# G32F031 register map
File version: 1.0
CPU: CM0PLUS r0p1, little endian, no MPU, no FPU, 2 interrupt priority bits
Registers are 32-bit, read-write, reset 0x0 unless marked. A register's access mark holds for its fields unless they carry their own. Offsets are from the block's base; [hi:lo] are bit positions; {n}, {i} and the like mark numbered series; 'fields as' and 'values as' point back to an identical list.

## COMP0 — Comparator
Base 0x40005C00
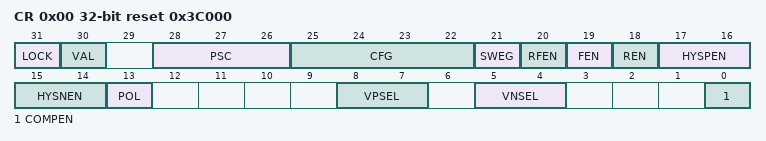
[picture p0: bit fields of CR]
0x00 CR access per field reset 0x3C000 — Control Register
  [31] LOCK rw
  [30] VAL ro — Comparator outputs the level value before polarity selector and shielding.
  [28:26] PSC rw — Digital filter fractional division configuration
  [25:22] CFG rw — Digital filter fractional clock configuration
  [21] SWEG rw — soft interrupt
  [20] RFEN rw — Comparator interrupt rising and falling edge enable
  [19] FEN rw — Comparator interrupt falling edge enable
  [18] REN rw — Comparator interrupt rising edge enable
  [17:16] HYSPEN rw — Delay function enabled
  [15:14] HYSNEN rw — Delay function enabled
  [13] POL rw — The output polarity of comparator .
  [8:7] VPSEL rw — Comparator positive input voltage selection
  [5:4] VNSEL rw — Comparator negative input voltage selection
  [0] COMPEN rw — Module enablement
0x04 ISR — Status register
  [0] IFLG — interrupt flag

## COMP1 — Comparator
Base 0x40006000
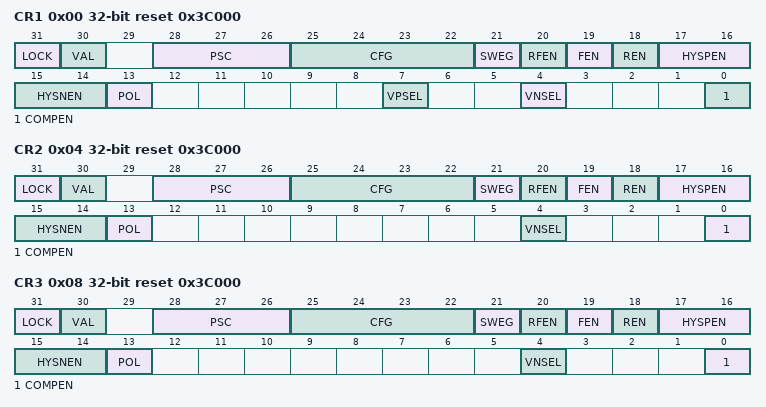
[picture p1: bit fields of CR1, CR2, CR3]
0x00 CR1 access per field reset 0x3C000 — Control Register 1
  [31] LOCK rw
  [30] VAL ro — Comparator outputs the level value before polarity selector and shielding.
  [28:26] PSC rw — Digital filter fractional division configuration
  [25:22] CFG rw — Digital filter fractional clock configuration
  [21] SWEG rw — soft interrupt
  [20] RFEN rw — Comparator interrupt rising and falling edge enable
  [19] FEN rw — Comparator interrupt falling edge enable
  [18] REN rw — Comparator interrupt rising edge enable
  [17:16] HYSPEN rw — Delay function enabled
  [15:14] HYSNEN rw — Delay function enabled
  [13] POL rw — The output polarity of comparator .
  [7] VPSEL rw — Comparator positive input voltage selection
  [4] VNSEL rw — Comparator negative input voltage selection
  [0] COMPEN rw — Module enablement
0x04 CR2 access per field reset 0x3C000 — Control Register 2
  [31] LOCK rw
  [30] VAL ro — Comparator outputs the level value before polarity selector and shielding.
  [28:26] PSC rw — Digital filter fractional division configuration
  [25:22] CFG rw — Digital filter fractional clock configuration
  [21] SWEG rw — soft interrupt
  [20] RFEN rw — Comparator interrupt rising and falling edge enable
  [19] FEN rw — Comparator interrupt falling edge enable
  [18] REN rw — Comparator interrupt rising edge enable
  [17:16] HYSPEN rw — Delay function enabled
  [15:14] HYSNEN rw — Delay function enabled
  [13] POL rw — The output polarity of comparator .
  [4] VNSEL rw — Comparator negative input voltage selection
  [0] COMPEN rw — Module enablement
0x08 CR3 access per field reset 0x3C000 — Control Register 3
  fields as CR2
{0x8+4i} ISR{i} (i=1..3) — Status register
  [0] IFLG — interrupt flag

## CRC — Cryptographic processor
Base 0x40020C00
0x00 DR — Data register
  [31:0] DATA — As an input register: stores new data for the CRC calculator when writing; As an output register: returns the result of the CRC calculation when reading.
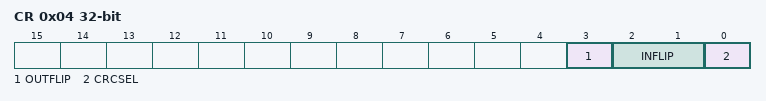
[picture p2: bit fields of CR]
0x04 CR — Control Register
  [3] OUTFLIP — Flip or not flip
  [2:1] INFLIP — Flip the input data in different units: do not flip, flip by byte, flip by half-word, flip by word.
  [0] CRCSEL — 32-bit, 16-bit CRC selection
0x08 INIT — Initial value data register
  [31:0] INIT — Setting the initial value of CRC.

## DIV
Base 0x40021000
0x00 DVDR — Dividend register
  [31:0] DIVIDEND
0x04 DVSR reset 0x1 — Divisor Register
  [31:0] DIVISOR
0x08 QUOTR wo — Quotient register
  [31:0] QUOTIENT
0x0C RMDR — Remainder register
  [31:0] REMAINDER
0x10 SR — Stauts register
  [0] OVFLG — Divide by zero overflow status flag
0x14 CR reset 0x1 — Control register
  [0] USIGNEN — Unsigned enable
